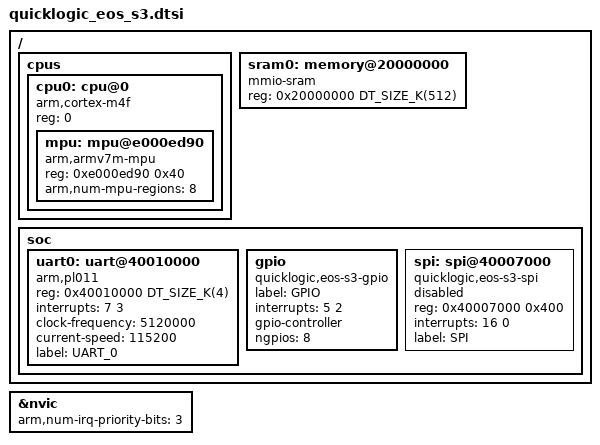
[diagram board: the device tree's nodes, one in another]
/*
 * Copyright (c) 2020 Antmicro <www.antmicro.com>
 *
 * SPDX-License-Identifier: Apache-2.0
 */

#include <mem.h>
#include <arm/armv7-m.dtsi>
#include <dt-bindings/gpio/gpio.h>

/ {
	cpus {
		#address-cells = <1>;
		#size-cells = <0>;

		cpu0: cpu@0 {
			device_type = "cpu";
			compatible = "arm,cortex-m4f";
			reg = <0>;
			#address-cells = <1>;
			#size-cells = <1>;

			mpu: mpu@e000ed90 {
				compatible = "arm,armv7m-mpu";
				reg = <0xe000ed90 0x40>;
				arm,num-mpu-regions = <8>;
			};
		};
	};

	sram0: memory@20000000 {
		compatible = "mmio-sram";
		reg = <0x20000000 DT_SIZE_K(512)>;
	};

	soc {
		uart0: uart@40010000 {
			compatible = "arm,pl011";
			reg = <0x40010000 DT_SIZE_K(4)>;
			interrupts = <7 3>;
			interrupt-names = "rx";
			clock-frequency = <5120000>;
			current-speed = <115200>;
			label = "UART_0";
		};

		gpio: gpio {
			compatible = "quicklogic,eos-s3-gpio";
			label = "GPIO";
			interrupts = <5 2>;
			interrupt-names = "gpio_irq";
			#gpio-cells = <2>;
			gpio-controller;
			ngpios = <8>;
		};

		spi: spi@40007000 {
			compatible = "quicklogic,eos-s3-spi";
			#address-cells = <1>;
			#size-cells = <0>;
			reg = <0x40007000 0x400>;
			interrupts = <16 0>;
			label = "SPI";
			status = "disabled";
		};
	};
};

&nvic {
	arm,num-irq-priority-bits = <3>;
};
